# LPC408x_7x register map
File version: 0.6
CPU: CM4 r0p0, little endian, no MPU, no FPU, 3 interrupt priority bits
Registers are 32-bit, read-write, reset 0x0 unless marked. A register's access mark holds for its fields unless they carry their own. Offsets are from the block's base; [hi:lo] are bit positions; {n}, {i} and the like mark numbered series; 'fields as' and 'values as' point back to an identical list.

## COMPARATOR — Comparators
Base 0x40020000
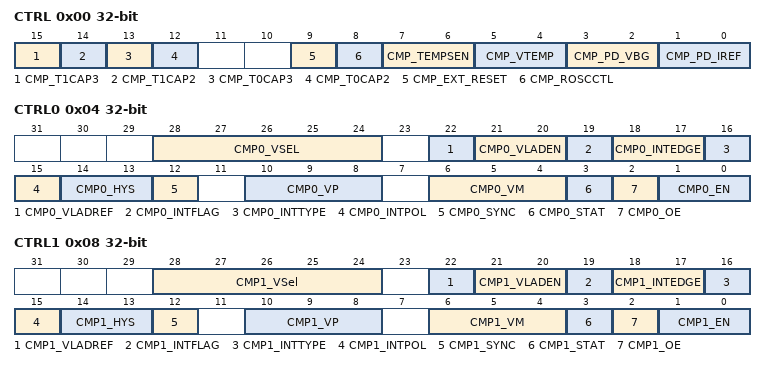
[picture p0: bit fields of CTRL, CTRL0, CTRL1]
0x00 CTRL — Comparator block control register
  [15] CMP_T1CAP3 — Selects the input for Timer 1 capture input 3.
    0=COMP1 (T1CAP3 is connected to comparator 1 level output.); 1=COMP0 (T1CAP3 is connected to comparator 0 edge output.)
  [14] CMP_T1CAP2 — Selects the input for Timer 1 capture input 2.
    0=COMP1 (T1CAP2 is connected to comparator 1 edge output.); 1=COMP0 (T1CAP2 is connected to comparator 0 level output.)
  [13] CMP_T0CAP3 — Selects the input for Timer 0 capture input 3.
    0=COMP0 (T0CAP3 is connected to comparator 0 edge output.); 1=COMP1 (T0CAP3 is connected to comparator 1 edge output.)
  [12] CMP_T0CAP2 — Selects the input for Timer 0 capture input 2.
    0=COMP0 (T0CAP2 is connected to comparator 0 level output.); 1=COMP1 (T0CAP2 is connected to comparator 1 level output.)
  [9] CMP_EXT_RESET — Selects the reset source for the CMP_ROSC output.
    0=INTRESET (The CMP_ROSC output is reset by the internal chip reset.); 1=CMP_RESETIN (The CMP_ROSC output is reset by the CMP_RESET input.)
  [8] CMP_ROSCCTL — Selects the inputs for the flip/flops that provide the CMP_ROSC output.
    0=CMP1 (The CMP_ROSC output is set by CMP1 and reset by CMP0.); 1=CMP0 (The CMP_ROSC output is set by CMP0 and reset by CMP1.)
  [7:6] CMP_TEMPSEN — Enables the temperature sensor. These bits must be set when the temperature sensor is used.
    0=DISABLED (Temperature sensor is disabled.); 1=DIS_DEEPSLP_PWRDWN (The temperature sensor is disabled in Deep Sleep and Power-down modes and restored automatically when exiting those modes.); 2=DIS_PWRDWN (The temperature sensor is disabled in Power-down mode and restored automatically when exiting Power-down.); 3=ENABLED (Temperature sensor is enabled.)
  [5:4] CMP_VTEMP — Controls the voltage reference of the temperature sensor. These bits must be set when the temperature sensor is used.
    0=DISABLED (The temperature sensor voltage reference is disabled.); 1=DIS_DEEPSLP_PWRDWN (The temperature sensor voltage reference is disabled in Deep Sleep and Power-down modes and restored automatically when exiting those modes.); 2=DIS_PWRDWN (The temperature sensor voltage reference is disabled in Power-down mode and restored automatically when exiting Power-down.); 3=ENABLED (The temperature sensor voltage reference is powered up.)
  [3:2] CMP_PD_VBG — Controls the bandgap reference source that is used by the comparators. These bits must be set when either comparator is used.
    0=DISABLED (The comparator bandgap reference is disabled.); 1=DIS_DEEPSLP_PWRDWN (The comparator bandgap reference is disabled in Deep Sleep and Power-down modes and restored automatically when exiting those modes.); 2=DIS_PWRDWN (The comparator bandgap reference is disabled in Power-down mode and restored automatically when exiting Power-down.); 3=ENABLED (The comparator bandgap reference is powered up.)
  [1:0] CMP_PD_IREF — Controls the current source used by the comparators. These bits must be set when either comparator is used.
    0=DISABLED (The comparator current source is disabled.); 1=DIS_DEEPSLP_PWRDWN (The comparator current source is disabled in Deep Sleep and Power-down modes and restored automatically when exiting those modes.); 2=DIS_PWRDWN (The comparator current source is disabled in Power-down mode and restored automatically when exiting Power-down.); 3=ENABLED (The comparator current source is powered up.)
0x04 CTRL0 — Comparator 0 control register
  [28:24] CMP0_VSEL — Voltage ladder value for comparator 0. The reference voltage Vref depends on the setting of CMP0_VLADREF (either VDD(3V3) or voltage on pin VREF_CMP). 00000 = Vss. 00001 = 1 x Vref0 / 31. 00010 = 2 x Vref0 / 31. ... 11111 = Vref0
  [22] CMP0_VLADREF — Voltage reference select for comparator 0 voltage ladder.
    0=VREF_CMP_PIN_; 1=VDDA_PIN_
  [21:20] CMP0_VLADEN — Voltage ladder enable for comparator 0.
    0=DISABLED (The Comparator 0 voltage ladder is disabled.); 1=DIS_DEEPSLP_PWRDWN (The Comparator 0 voltage ladder is disabled in Deep Sleep and Power-down modes and re-enabled automatically when exiting those modes.); 2=DIS_PWRDWN (The Comparator 0 voltage ladder is disabled in Power-down mode and re-enabled automatically when exiting Power-down.); 3=ENABLED (The Comparator 0 voltage ladder is enabled.)
  [19] CMP0_INTFLAG — Comparator 0 interrupt flag.
    0=NOTPENDING (The Comparator 0 interrupt is not pending.); 1=PENDING (The Comparator 0 interrupt is pending. Writing a 1 to this bit clears the flag.)
  [18:17] CMP0_INTEDGE — Select edge triggered interrupt to be active on either high or low transitions, when CMP0_IntType = 0. See Table 412.
    0=FALLING (Comparator 0 interrupt is active on falling edges.); 1=RISING (Comparator 0 interrupt is active on rising edges.); 2=DUALEDGE (Comparator 0 Interrupt is active on both edges.)
  [16] CMP0_INTTYPE — Select comparator 0 interrupt type. See Table 412.
    0=EDGE (Comparator 0 interrupt is edge triggered.); 1=LEVEL (Comparator 0 interrupt is level triggered.)
  [15] CMP0_INTPOL — Selects the polarity of the CMP0 output for purposes of generating level interrupts. See Table 412.
    0=NOTINVERTED (The CMP0 output is used as-is for generating interrupts.); 1=INVERTED (The CMP0 output is used inverted for generating interrupts.)
  [14:13] CMP0_HYS — Comparator 0 hysteresis control. When enabled, hysteresis determines the difference required between the comparator inputs before the comparator output switches. The difference must be in the direction opposite of the current comparator output.
    0=HYSTERESISOFF (Hysteresis is turned off, comparator output will change as the input voltages cross.); 1=HYSTERESIS_EQ_5_MV_ (Hysteresis = 5 mV.); 2=HYSTERESIS_EQ_10_MV_ (Hysteresis = 10 mV.); 3=HYSTERESIS_EQ_15_MV_ (Hysteresis = 15 mV.)
  [12] CMP0_SYNC — Comparator 0 output synchronization control.
    0=DIRECT (The comparator 0 output is used directly.); 1=SYNCH (The comparator 0 output is synchronized with the internal bus clock for output to other peripherals.)
  [10:8] CMP0_VP — Comparator 0 VP input select.
    0=VREF_DIVIDER_0_; {v}=CMP0_IN{v-1} (v=1..4); 5=CMP1_IN0; 6=INTERNAL_0_9_V_BAND_ (internal 0.9 V band gap reference.); 7=TEMPERATURE_SENSOR_
  [6:4] CMP0_VM — Comparator 0 VM input select.
    values as CMP0_VP
  [3] CMP0_STAT — Comparator 0 status. This bit reflects the comparator 0 output, and is not affected by CMP0_OE.
  [2] CMP0_OE — Comparator 0 output enable.
    0=DISABLED (Comparator 0 output is disabled.); 1=ENABLED (Comparator 0 output is enabled.)
  [1:0] CMP0_EN — Comparator 0 enable control.
    0=DISABLED (Comparator 0 disabled.); 1=DIS_DEEPSLP_PWRDWN (Comparator 0 is disabled in Deep Sleep and Power-down modes and re-enabled automatically when exiting those modes.); 2=DIS_PWRDWN (Comparator 0 is disabled in Power-down mode and re-enabled automatically when exiting Power-down.); 3=ENABLED (Comparator 0 is enabled.)
0x08 CTRL1 — Comparator 1 control register
  [28:24] CMP1_VSel — Voltage ladder value for comparator 1. The reference voltage Vref depends on the setting of CMP1_VLADREF (either VDD(3V3) or voltage on pin VREF_CMP). 00000 = Vss. 00001 = 1 x Vref1 / 31. 00010 = 2 x Vref1 / 31. ... 11111 = Vref1.
  [22] CMP1_VLADREF — Voltage reference select for comparator 1 voltage ladder.
    0=VREF_CMP_PIN_; 1=VDDA_PIN_
  [21:20] CMP1_VLADEN — Voltage ladder enable for comparator 1.
    0=DISABLED (The Comparator 1 voltage ladder is disabled.); 1=DIS_DEEPSLP_PWRDWN (The Comparator 1 voltage ladder is disabled in Deep Sleep and Power-down modes and re-enabled automatically when exiting those modes.); 2=DIS_PWRDWN (The Comparator 1 voltage ladder is disabled in Power-down mode and re-enabled automatically when exiting Power-down.); 3=ENABLED (The Comparator 1 voltage ladder is enabled.)
  [19] CMP1_INTFLAG — Comparator 1 interrupt flag.
    0=NOTPENDING (The Comparator 1 interrupt is not pending.); 1=PENDING (The Comparator 1 interrupt is pending. Writing a 1 to this bit clears the flag.)
  [18:17] CMP1_INTEDGE — Select edge triggered interrupt to be active on either high or low transitions, when CMP1_IntType = 0. See Table 412.
    0=FALLING (Comparator 1 interrupt is active on falling edges.); 1=RISING (Comparator 1 interrupt is active on rising edges.); 2=DUALEDGE (Comparator 1 Interrupt is active on both edges.)
  [16] CMP1_INTTYPE — Select comparator 1 interrupt type. See Table 412.
    0=EDGE (Comparator 1 interrupt is edge triggered.); 1=LEVEL (Comparator 1 interrupt is level triggered.)
  [15] CMP1_INTPOL — Selects the polarity of the CMP1 output for purposes of generating level interrupts. See Table 412.
    0=NOTINVERTED (The CMP1 output is used as-is for generating interrupts.); 1=INVERTED (The CMP1 output is used inverted for generating interrupts.)
  [14:13] CMP1_HYS — Comparator 1 hysteresis control. When enabled, hysteresis determines the difference required between the comparator inputs before the comparator output switches. The difference must be in the direction opposite of the current comparator output.
    values as CTRL0.CMP0_HYS
  [12] CMP1_SYNC — Comparator 1 output synchronization control.
    0=DIRECT (The comparator 1 output is used directly.); 1=SYNCH (The comparator 1 output is synchronized with the internal bus clock for output to other peripherals.)
  [10:8] CMP1_VP — Comparator 1 VP input select.
    0=VREF_DIVIDER_0_; {v}=CMP1_IN{v-1} (v=1..4); 5=CMP0_IN0; 6=INTERNAL_0_9_V_BAND_ (internal 0.9 V band gap reference.); 7=TEMPERATURE_SENSOR_
  [6:4] CMP1_VM — Comparator 1 VM input select.
    0=VREF_DIVIDER_1_; {v}=CMP1_IN{v-1} (v=1..4); 5=CMP0_IN0; 6=INTERNAL_0_9_V_BAND_ (internal 0.9 V band gap reference.); 7=TEMPERATURE_SENSOR_
  [3] CMP1_STAT — Comparator 1 status. This bit reflects the comparator 1 output, and is not affected by CMP1_OE.
  [2] CMP1_OE — Comparator 1 output enable.
    0=DISABLED (Comparator 1 output is disabled.); 1=ENABLED (Comparator 1 output is enabled.)
  [1:0] CMP1_EN — Comparator 1 enable control.
    0=DISABLED (Comparator 1 disabled.); 1=DIS_DEEPSLP_PWRDWN (Comparator 1 is disabled in Deep Sleep and Power-down modes and re-enabled automatically when exiting those modes.); 2=DIS_PWRDWN (Comparator 1 is disabled in Power-down mode and re-enabled automatically when exiting Power-down.); 3=ENABLED (Comparator 1 is enabled.)
